# A64 register map
Vendor: Allwinner; Series: A64; File version: 0.1
CPU: CA53 0, little endian, MPU, no FPU, 0 interrupt priority bits
Registers are 32-bit, read-write, reset 0x0 unless marked. A register's access mark holds for its fields unless they carry their own. Offsets are from the block's base; [hi:lo] are bit positions; {n}, {i} and the like mark numbered series.

## PIO
Base 0x01F02C00
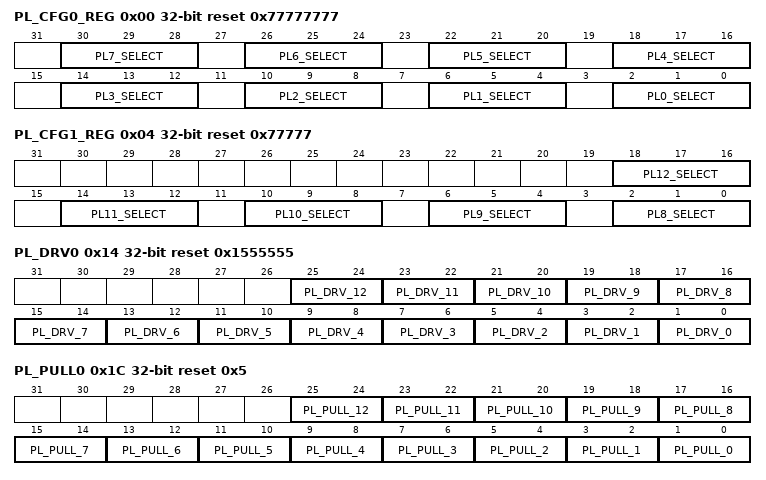
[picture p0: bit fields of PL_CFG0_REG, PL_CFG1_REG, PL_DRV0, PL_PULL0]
0x00 PL_CFG0_REG reset 0x77777777
  [30:28] PL7_SELECT — 000: Input 001: Output 010: S_JTAG_DI 011: Reserved 100: Reserved 101: Reserved 110: S_PL_EINT7 111: IO Disable
    0=Input; 1=Output; 2=S_JTAG_DI; 6=S_PL_EINT7; 7=IO (IO Disable)
  [26:24] PL6_SELECT — 000: Input 001: Output 010: S_JTAG_DO 011: Reserved 100: Reserved 101: Reserved 110: S_PL_EINT6 111: IO Disable
    0=Input; 1=Output; 2=S_JTAG_DO; 6=S_PL_EINT6; 7=IO (IO Disable)
  [22:20] PL5_SELECT — 000: Input 001: Output 010: S_JTAG_CK 011: Reserved 100: Reserved 101: Reserved 110: S_PL_EINT5 111: IO Disable
    0=Input; 1=Output; 2=S_JTAG_CK; 6=S_PL_EINT5; 7=IO (IO Disable)
  [18:16] PL4_SELECT — 000: Input 001: Output 010: S_JTAG_MS 011: Reserved 100: Reserved 101: Reserved 110: S_PL_EINT4 111: IO Disable
    0=Input; 1=Output; 2=S_JTAG_MS; 6=S_PL_EINT4; 7=IO (IO Disable)
  [14:12] PL3_SELECT — 000: Input 001: Output 010: S_UART_RX 011: Reserved 100: Reserved 101: Reserved 110: S_PL_EINT3 111: IO Disable
    0=Input; 1=Output; 2=S_UART_RX; 6=S_PL_EINT3; 7=IO (IO Disable)
  [10:8] PL2_SELECT — 000: Input 001: Output 010: S_UART_TX 011: Reserved 100: Reserved 101: Reserved 110: S_PL_EINT2 111: IO Disable
    0=Input; 1=Output; 2=S_UART_TX; 6=S_PL_EINT2; 7=IO (IO Disable)
  [6:4] PL1_SELECT — 000: Input 001: Output 010: S_RSB_SDA 011: S_TWI_SDA 100: Reserved 101: Reserved 110: S_PL_EINT1 111: IO Disable
    0=Input; 1=Output; 2=S_RSB_SDA; 3=S_TWI_SDA; 6=S_PL_EINT1; 7=IO (IO Disable)
  [2:0] PL0_SELECT — 000: Input 001: Output 010: S_RSB_SCK 011: S_TWI_SCK 100: Reserved 101: Reserved 110: S_PL_EINT0 111: IO Disable
    0=Input; 1=Output; 2=S_RSB_SCK; 3=S_TWI_SCK; 6=S_PL_EINT0; 7=IO (IO Disable)
0x04 PL_CFG1_REG reset 0x77777
  [18:16] PL12_SELECT — 000: Input 001: Output 010: Reserved 011: Reserved 100: Reserved 101: Reserved 110: S_PL_EINT12 111: IO Disable
    0=Input; 1=Output; 6=S_PL_EINT12; 7=IO (IO Disable)
  [14:12] PL11_SELECT — 000: Input 001: Output 010: S_CIR_RX 011: Reserved 100: Reserved 101: Reserved 110: S_PL_EINT11 111: IO Disable
    0=Input; 1=Output; 2=S_CIR_RX; 6=S_PL_EINT11; 7=IO (IO Disable)
  [10:8] PL10_SELECT — 000: Input 001: Output 010: S_PWM 011: Reserved 100: Reserved 101: Reserved 110: S_PL_EINT10 111: IO Disable
    0=Input; 1=Output; 2=S_PWM; 6=S_PL_EINT10; 7=IO (IO Disable)
  [6:4] PL9_SELECT — 000: Input 001: Output 010: S_TWI_SDA 011: Reserved 100: Reserved 101: Reserved 110: S_PL_EINT9 111: IO Disable
    0=Input; 1=Output; 2=S_TWI_SDA; 6=S_PL_EINT9; 7=IO (IO Disable)
  [2:0] PL8_SELECT — 000: Input 001: Output 010: S_TWI_SCK 011: Reserved 100: Reserved 101: Reserved 110: S_PL_EINT8 111: IO Disable
    0=Input; 1=Output; 2=S_TWI_SCK; 6=S_PL_EINT8; 7=IO (IO Disable)
0x08 PL_CFG2_REG reset not defined
0x0C PL_CFG3_REG reset not defined
0x10 PL_DATA_REG
  [12:0] PL_DAT — If the port is configured as input, the corresponding bit is the pin state. If the port is configured as output, the pin state is the same as the corresponding bit. The read bit value is the value setup by software. If the port is configured as functional pin, the undefined value will be read.
0x14 PL_DRV0 reset 0x1555555 — Port L Multi-Driving Register 0
  [2n+1:2n] PL_DRV_{n} (n=0..12) — PL[n] Multi-Driving Select (n = 0~12) 00: Level 0 01: Level 1 10: Level 2 11: Level 3
0x18 PL_DRV1 reset not defined — Port L Multi-Driving Register 1
0x1C PL_PULL0 reset 0x5
  [2n+1:2n] PL_PULL_{n} (n=0..12) — PL[n] Pull-up/down Select (n = 0~12) 00: Pull-up/down disable 01: Pull-up 10: Pull-down 11: Reserved
0x20 PL_PULL1 reset not defined
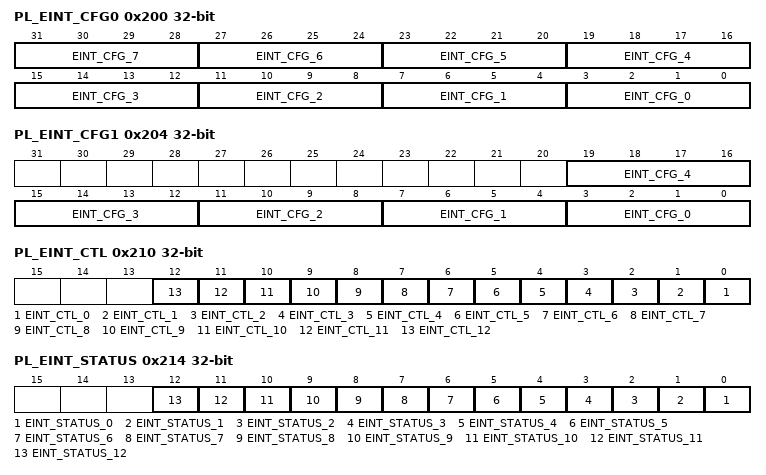
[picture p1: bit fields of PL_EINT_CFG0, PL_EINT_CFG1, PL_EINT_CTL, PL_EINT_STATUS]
0x200 PL_EINT_CFG0
  [4n+3:4n] EINT_CFG_{n} (n=0..7) — External INTn Mode (n = 0~7) 0x0: Positive Edge 0x1: Negative Edge 0x2: High Level 0x3: Low Level 0x4: Double Edge (Positive/ Negative) Others: Reserved
0x204 PL_EINT_CFG1
  [4n+3:4n] EINT_CFG_{n} (n=0..4) — External INTn Mode (n = 8~12) 0x0: Positive Edge 0x1: Negative Edge 0x2: High Level 0x3: Low Level 0x4: Double Edge (Positive/ Negative) Others: Reserved
0x208 PL_EINT_CFG2 reset not defined
0x20C PL_EINT_CFG3 reset not defined
0x210 PL_EINT_CTL
  [n] EINT_CTL_{n} (n=0..12) — External INTn Enable (n = 0~12) 0: Disable 1: Enable
0x214 PL_EINT_STATUS
  [n] EINT_STATUS_{n} (n=0..12) — External INTn Pending Bit (n = 0~12) 0: No IRQ pending 1: IRQ pending Write `1` to clear
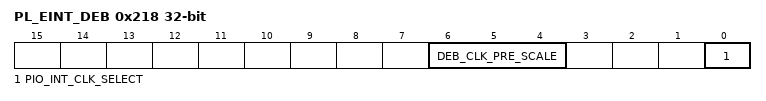
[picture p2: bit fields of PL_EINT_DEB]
0x218 PL_EINT_DEB
  [6:4] DEB_CLK_PRE_SCALE — Debounce Clock Pre-scale n The selected clock source is prescaled by 2^n.
  [0] PIO_INT_CLK_SELECT — PIO Interrupt Clock Select 0: LOSC 32KHz 1: HOSC 24MHz
    0=LOSC (LOSC 32KHz); 1=HOSC (HOSC 24MHz)
